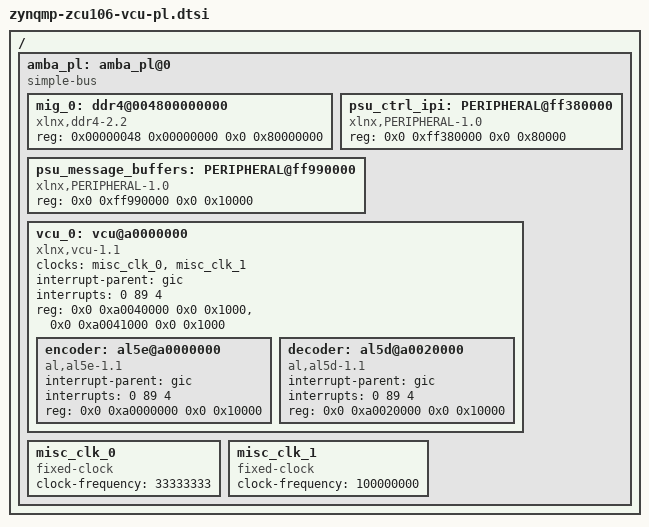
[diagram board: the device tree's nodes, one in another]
/*
 * CAUTION: This file is automatically generated by Xilinx.
 * Version:  
 * Today is: Tue Apr 17 07:23:24 2018
 */


/ {
	amba_pl: amba_pl@0 {
		#address-cells = <2>;
		#size-cells = <2>;
		compatible = "simple-bus";
		ranges ;
		mig_0: ddr4@004800000000 {
			compatible = "xlnx,ddr4-2.2";
			reg = <0x00000048 0x00000000 0x0 0x80000000>;
		};
		psu_ctrl_ipi: PERIPHERAL@ff380000 {
			compatible = "xlnx,PERIPHERAL-1.0";
			reg = <0x0 0xff380000 0x0 0x80000>;
		};
		psu_message_buffers: PERIPHERAL@ff990000 {
			compatible = "xlnx,PERIPHERAL-1.0";
			reg = <0x0 0xff990000 0x0 0x10000>;
		};
		vcu_0: vcu@a0000000 {
			#address-cells = <2>;
			#size-cells = <2>;
			clock-names = "pll_ref", "aclk";
			clocks = <&misc_clk_0>, <&misc_clk_1>;
			compatible = "xlnx,vcu-1.1", "xlnx,vcu";
			interrupt-names = "vcu_host_interrupt";
			interrupt-parent = <&gic>;
			interrupts = <0 89 4>;
			ranges ;
			reg = <0x0 0xa0040000 0x0 0x1000>,
				<0x0 0xa0041000 0x0 0x1000>;
			reg-names = "vcu_slcr", "logicore";
			encoder: al5e@a0000000 {
				compatible = "al,al5e-1.1", "al,al5e";
				interrupt-parent = <&gic>;
				interrupts = <0 89 4>;
				reg = <0x0 0xa0000000 0x0 0x10000>;
			};
			decoder: al5d@a0020000 {
				compatible = "al,al5d-1.1", "al,al5d";
				interrupt-parent = <&gic>;
				interrupts = <0 89 4>;
				reg = <0x0 0xa0020000 0x0 0x10000>;
			};
		};
		misc_clk_0: misc_clk_0 {
			#clock-cells = <0>;
			clock-frequency = <33333333>;
			compatible = "fixed-clock";
		};
		misc_clk_1: misc_clk_1 {
			#clock-cells = <0>;
			clock-frequency = <100000000>;
			compatible = "fixed-clock";
		};
	};
};
